# STM32WBA25 register map
File version: 1.0
CPU: CM33 r0p1, little endian, MPU, FPU, 4 interrupt priority bits
Registers are 32-bit, read-write, reset 0x0 unless marked. A register's access mark holds for its fields unless they carry their own. Offsets are from the block's base; [hi:lo] are bit positions; {n}, {i} and the like mark numbered series; 'fields as' and 'values as' point back to an identical list.

## EXTI — EXTI address block description
Base 0x46022000
Same registers: SEC_EXTI 0x56022000
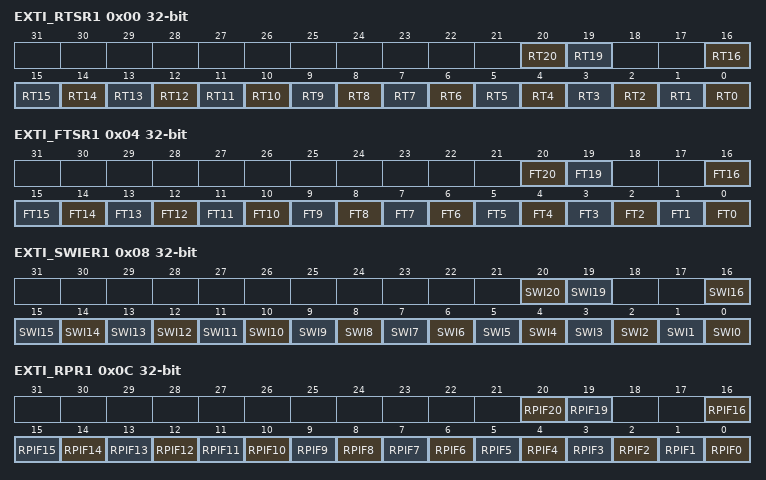
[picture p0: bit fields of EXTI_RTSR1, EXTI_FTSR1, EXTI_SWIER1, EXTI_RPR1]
0x00 EXTI_RTSR1 — EXTI rising trigger selection register
  [20] RT20 — Rising trigger event configuration bit of configurable event input xless thansup>(1)less than/sup>
    0=Rising trigger disabled (for event and interrupt) for input line; 1=Rising trigger enabled (for event and interrupt) for input line
  [19] RT19 — Rising trigger event configuration bit of configurable event input xless thansup>(1)less than/sup>
    values as RT20
  [n] RT{n} (n=0..16) — Rising trigger event configuration bit of configurable event input x
0x04 EXTI_FTSR1 — EXTI falling trigger selection register
  [20] FT20 — Falling trigger event configuration bit of configurable event input xless thansup>(1)less than/sup>
    0=Falling trigger disabled (for event and Interrupt) for input line; 1=Falling trigger enabled (for event and Interrupt) for input line
  [19] FT19 — Falling trigger event configuration bit of configurable event input xless thansup>(1)less than/sup>
    values as FT20
  [n] FT{n} (n=0..16) — Falling trigger event configuration bit of configurable event input x
0x08 EXTI_SWIER1 — EXTI software interrupt event register
  [20] SWI20 — Software interrupt on event x
    0=Writing 0 has no effect; 1=Writing 1 triggers a rising edge event on event x
  [19] SWI19 — Software interrupt on event x
    values as SWI20
  [n] SWI{n} (n=0..16) — Software interrupt on event x
0x0C EXTI_RPR1 — EXTI rising edge pending register
  [20] RPIF20 — configurable event inputs x rising edge pending bit
    0=No rising edge trigger request occurred; 1=Rising edge trigger request occurred
  [19] RPIF19 — configurable event inputs x rising edge pending bit
    values as RPIF20
  [n] RPIF{n} (n=0..16) — configurable event inputs x rising edge pending bit
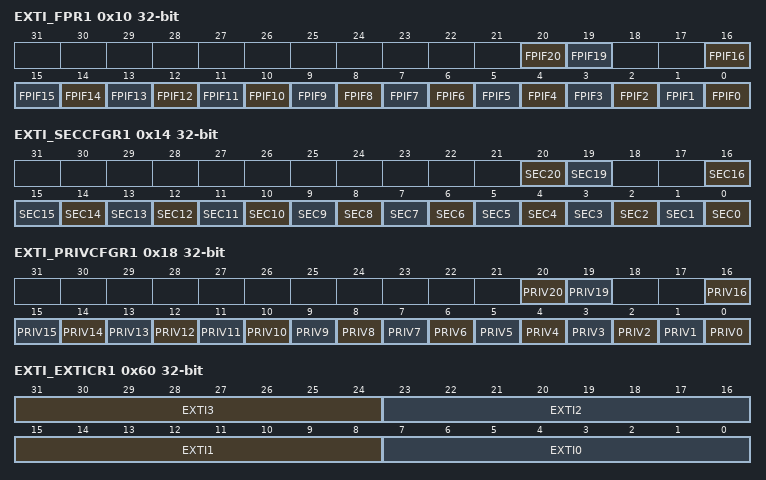
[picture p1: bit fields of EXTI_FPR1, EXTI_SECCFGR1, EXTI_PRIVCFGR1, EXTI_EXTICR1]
0x10 EXTI_FPR1 — EXTI falling edge pending register
  [20] FPIF20 — configurable event inputs x falling edge pending bit
    0=No falling edge trigger request occurred; 1=Falling edge trigger request occurred
  [19] FPIF19 — configurable event inputs x falling edge pending bit
    values as FPIF20
  [n] FPIF{n} (n=0..16) — configurable event inputs x falling edge pending bit
0x14 EXTI_SECCFGR1 — EXTI security configuration register
  [20] SEC20 — Security enable on event input x
    0=event security disabled (nonsecure); 1=event security enabled (secure)
  [19] SEC19 — Security enable on event input x
    values as SEC20
  [n] SEC{n} (n=0..16) — Security enable on event input x
0x18 EXTI_PRIVCFGR1 — EXTI privilege configuration register
  [20] PRIV20 — Security enable on event input x
    0=event privilege disabled (unprivileged); 1=event privilege enabled (privileged)
  [19] PRIV19 — Security enable on event input x
    values as PRIV20
  [n] PRIV{n} (n=0..16) — Security enable on event input x
0x60 EXTI_EXTICR1 — EXTI external interrupt selection register
  [31:24] EXTI3 — EXTI3 GPIO port selection
    1=PB3 pin; 7=PH3 pin
  [23:16] EXTI2 — EXTI2 GPIO port selection
    0=PA2 pin; 1=PB2 pin
  [15:8] EXTI1 — EXTI1 GPIO port selection
    0=PA1 pin
  [7:0] EXTI0 — EXTI0 GPIO port selection
    0=PA0 pin
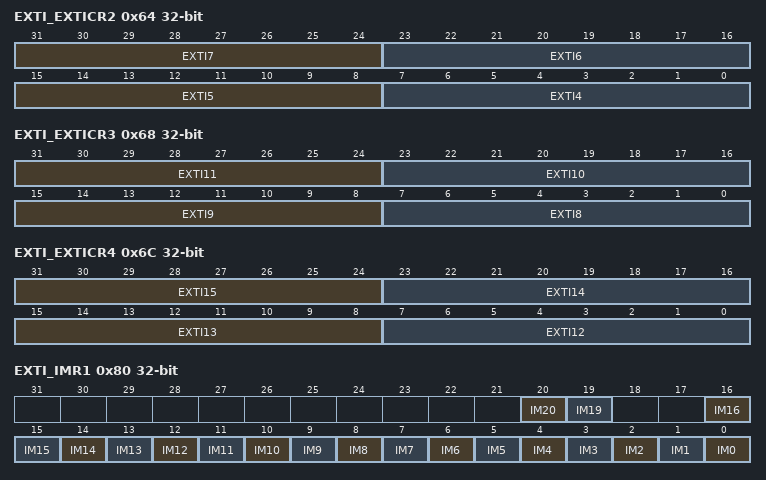
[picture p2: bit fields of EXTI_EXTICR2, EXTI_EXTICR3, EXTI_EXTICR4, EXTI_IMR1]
0x64 EXTI_EXTICR2 — EXTI external interrupt selection register
  [31:24] EXTI7 — EXTI7 GPIO port selection
    0=PA7 pin
  [23:16] EXTI6 — EXTI6 GPIO port selection
    0=PA6 pin; 1=PB6 pin
  [15:8] EXTI5 — EXTI5 GPIO port selection
    0=PA5 pin; 1=PB5 pin
  [7:0] EXTI4 — EXTI4 GPIO port selection
    1=PB4 pin
0x68 EXTI_EXTICR3 — EXTI external interrupt selection register
  [31:24] EXTI11 — EXTI11 GPIO port selection
    0=PA11 pin
  [23:16] EXTI10 — EXTI10 GPIO port selection
    0=PA10 pin
  [15:8] EXTI9 — EXTI9 GPIO port selection
    0=PA9 pin; 1=PB9 pin
  [7:0] EXTI8 — EXTI8 GPIO port selection
    0=PA8 pin; 1=PB8 pin
0x6C EXTI_EXTICR4 — EXTI external interrupt selection register
  [31:24] EXTI15 — EXTI15 GPIO port selection
    0=PA15 pin; 1=PB15 pin; 2=PC15 pin
  [23:16] EXTI14 — EXTI14 GPIO port selection
    0=PA14 pin; 2=PC14 pin
  [15:8] EXTI13 — EXTI13 GPIO port selection
    0=PA13 pin; 2=PC13 pin
  [7:0] EXTI12 — EXTI0 GPIO port selection
    0=PA12 pin; 1=PB12 pin
0x70 EXTI_LOCKR — EXTI lock register
  [0] LOCK — Global security and privilege configuration registers (EXTI_SECCFGR and EXTI_PRIVCFGR) lock
    0=security and privilege configuration open, can be modified; 1=security and privilege configuration locked, can no longer be modified
0x80 EXTI_IMR1 — EXTI CPU wakeup with interrupt mask register
  [20] IM20 — CPU wakeup with interrupt mask on event input xless thansup>(1)less than/sup>
    0=Wakeup with interrupt request from input event x is masked; 1=Wakeup with interrupt request from input event x is unmasked
  [19] IM19 — CPU wakeup with interrupt mask on event input xless thansup>(1)less than/sup>
    values as IM20
  [n] IM{n} (n=0..16) — CPU wakeup with interrupt mask on event input x
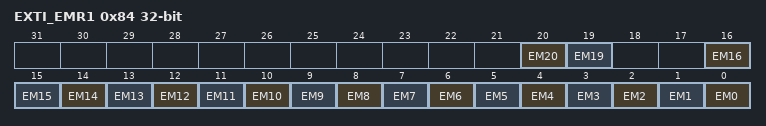
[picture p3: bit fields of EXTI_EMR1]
0x84 EXTI_EMR1 — EXTI CPU wakeup with event mask register
  [20] EM20 — CPU wakeup with event generation mask on event input x
    0=Wakeup with event generation from Line x is masked; 1=Wakeup with event generation from Line x is unmasked
  [19] EM19 — CPU wakeup with event generation mask on event input x
    values as EM20
  [n] EM{n} (n=0..16) — CPU wakeup with event generation mask on event input x
